# Cortex-M35P register map
Vendor: ARM Ltd.
CPU: Cortex-M35P r0p0, little endian, MPU, FPU, double-precision FPU, VTOR, vendor SysTick, 8 interrupt priority bits
Registers are 32-bit, read-write, no defined reset value unless marked. A register's access mark holds for its fields unless they carry their own. Offsets are from the block's base; [hi:lo] are bit positions; {n}, {i} and the like mark numbered series; 'fields as' and 'values as' point back to an identical list.

## NVIC — Nested Vectored Interrupt Controller
Base ?
0x00 NVIC_ISER{i} (i=0..15)
  [30:0] SETENA — Set enable
0x00 NVIC_ISPR{i} (i=0..15)
  [30:0] SETPEND — Set pending
0x80 NVIC_ICER{i} (i=0..15)
  [30:0] CLRENA — Clear enable
0x180 NVIC_ICPR{i} (i=0..15)
  [30:0] CLRPEND — Clear pending
0x200 NVIC_IABR{i} ro (i=0..15)
  [30:0] ACTIVE — Active state
0x280 NVIC_ITNS{i} (i=0..15)
  [30:0] ITNS — Interrupt Targets Non-secure
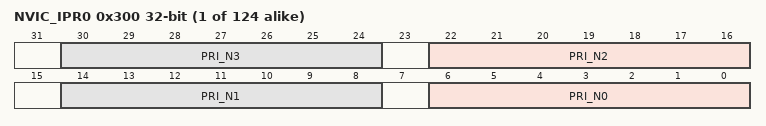
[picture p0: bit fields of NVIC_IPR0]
0x300 NVIC_IPR{i} (i=0..123)
  [8n+6:8n] PRI_N{n} (n=0..3) — Priority '{4i}'+{n}

## MPU — Memory protection Unit Control Registers
Base ?
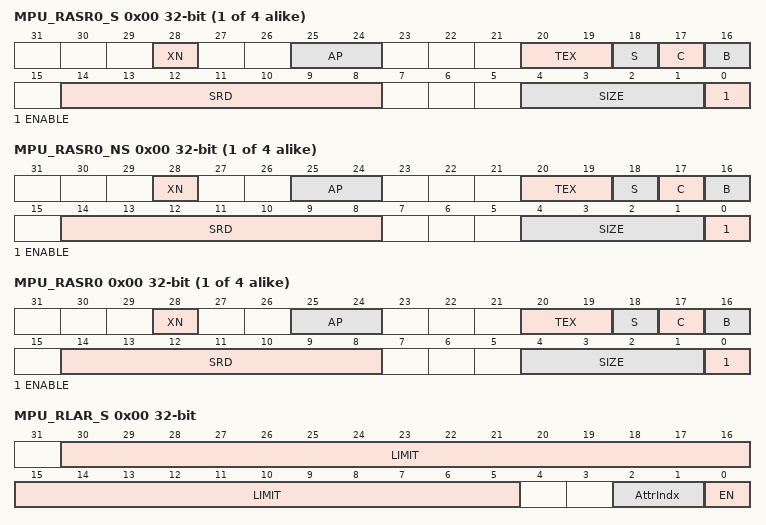
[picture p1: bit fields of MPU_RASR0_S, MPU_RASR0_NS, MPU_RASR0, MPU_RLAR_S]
0x00 MPU_RASR{i}_S (i=0..3)
  [28] XN, [25:24] AP, [20:19] TEX, [18] S, [17] C, [16] B, [14:8] SRD, [4:1] SIZE, [0] ENABLE
0x00 MPU_RASR{i}_NS (i=0..3)
  fields as MPU_RASR0_S
0x00 MPU_RASR{i} (i=0..3)
  fields as MPU_RASR0_S
0x00 MPU_RLAR_S
  [30:5] LIMIT — Limit address
  [2:1] AttrIndx — Attribute index
  [0] EN — Enable
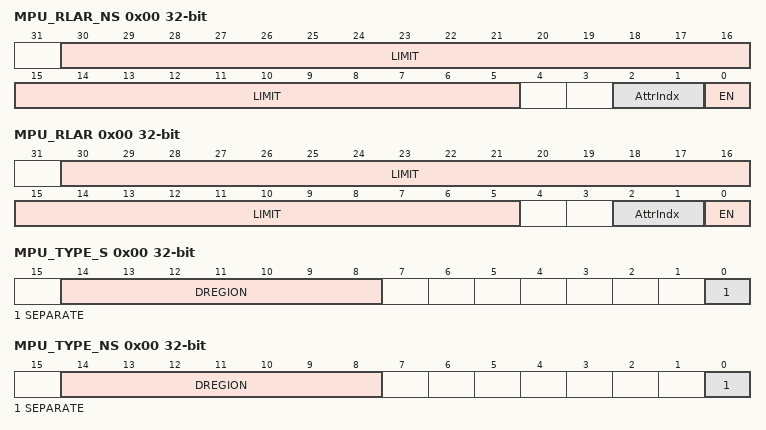
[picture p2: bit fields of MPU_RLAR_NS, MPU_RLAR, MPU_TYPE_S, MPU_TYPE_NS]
0x00 MPU_RLAR_NS
  fields as MPU_RLAR_S
0x00 MPU_RLAR
  fields as MPU_RLAR_S
0x00 MPU_TYPE_S ro
  [14:8] DREGION — Data regions
  [0] SEPARATE
0x00 MPU_TYPE_NS ro
  [14:8] DREGION — Data regions
  [0] SEPARATE
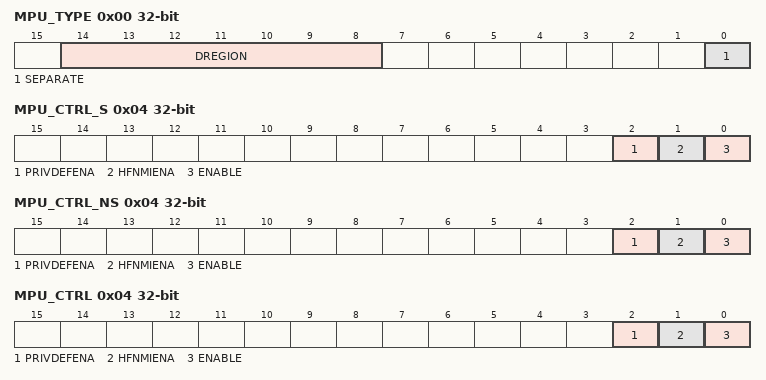
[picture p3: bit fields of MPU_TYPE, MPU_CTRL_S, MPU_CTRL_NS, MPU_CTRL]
0x00 MPU_TYPE ro
  [14:8] DREGION — Data regions
  [0] SEPARATE
0x04 MPU_CTRL_S
  [2] PRIVDEFENA — Privileged default enable
  [1] HFNMIENA — HardFault, NMI enable
  [0] ENABLE
0x04 MPU_CTRL_NS
  fields as MPU_CTRL_S
0x04 MPU_CTRL
  fields as MPU_CTRL_S
0x08 MPU_RNR_S
  [6:0] REGION — Region number
0x08 MPU_RNR_NS
  [6:0] REGION — Region number
0x08 MPU_RNR
  [6:0] REGION — Region number
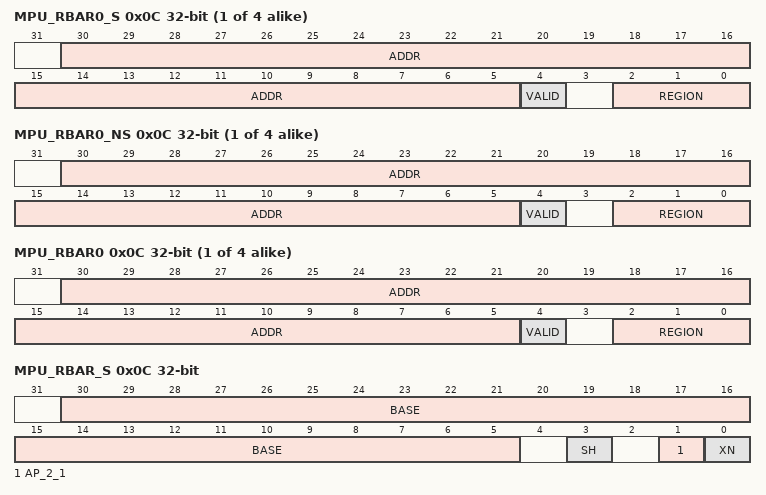
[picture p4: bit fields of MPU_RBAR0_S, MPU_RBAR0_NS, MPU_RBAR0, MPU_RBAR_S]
0x0C MPU_RBAR{i}_S (i=0..3)
  [30:5] ADDR, [4] VALID, [2:0] REGION
0x0C MPU_RBAR{i}_NS (i=0..3)
  [30:5] ADDR, [4] VALID, [2:0] REGION
0x0C MPU_RBAR{i} (i=0..3)
  [30:5] ADDR, [4] VALID, [2:0] REGION
0x0C MPU_RBAR_S
  [30:5] BASE — Base address
  [3] SH — Shareability
  [1] AP_2_1 — Access permissions
  [0] XN — Execute Never
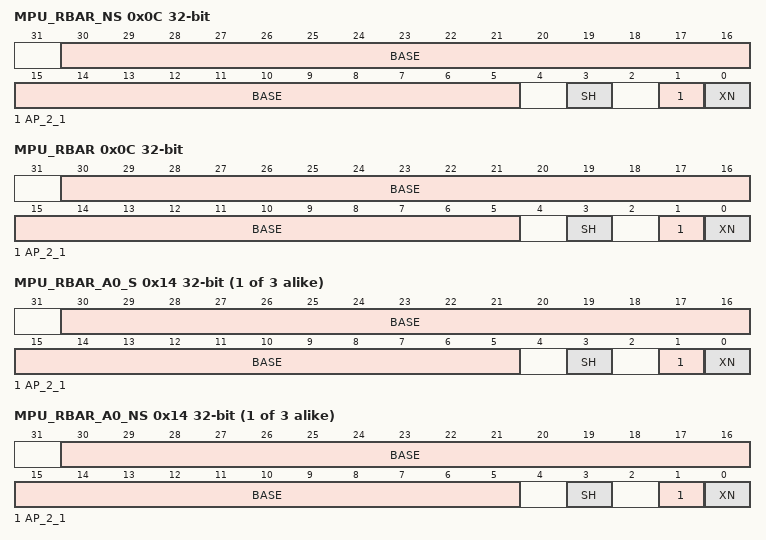
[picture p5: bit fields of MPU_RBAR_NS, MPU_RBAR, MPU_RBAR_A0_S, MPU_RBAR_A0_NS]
0x0C MPU_RBAR_NS
  fields as MPU_RBAR_S
0x0C MPU_RBAR
  fields as MPU_RBAR_S
0x14 MPU_RBAR_A{i}_S (i=0..2)
  fields as MPU_RBAR_S
0x14 MPU_RBAR_A{i}_NS (i=0..2)
  fields as MPU_RBAR_S
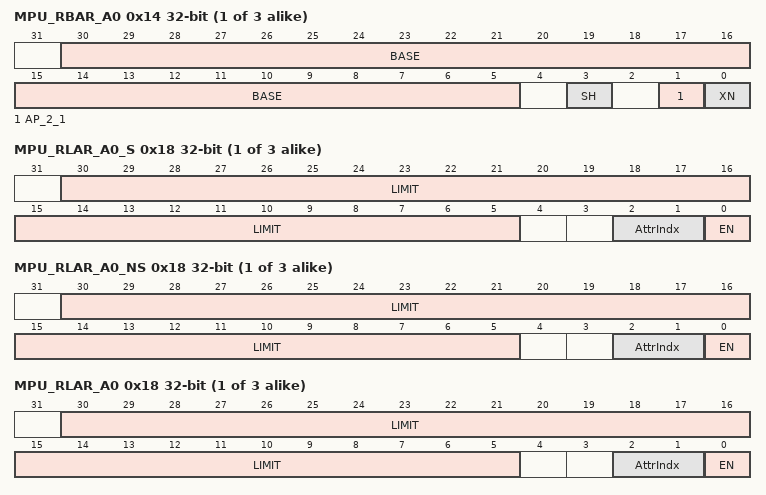
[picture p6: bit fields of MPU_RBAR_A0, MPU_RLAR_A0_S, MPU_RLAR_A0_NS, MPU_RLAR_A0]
0x14 MPU_RBAR_A{i} (i=0..2)
  fields as MPU_RBAR_S
0x18 MPU_RLAR_A{i}_S (i=0..2)
  fields as MPU_RLAR_S
0x18 MPU_RLAR_A{i}_NS (i=0..2)
  fields as MPU_RLAR_S
0x18 MPU_RLAR_A{i} (i=0..2)
  fields as MPU_RLAR_S
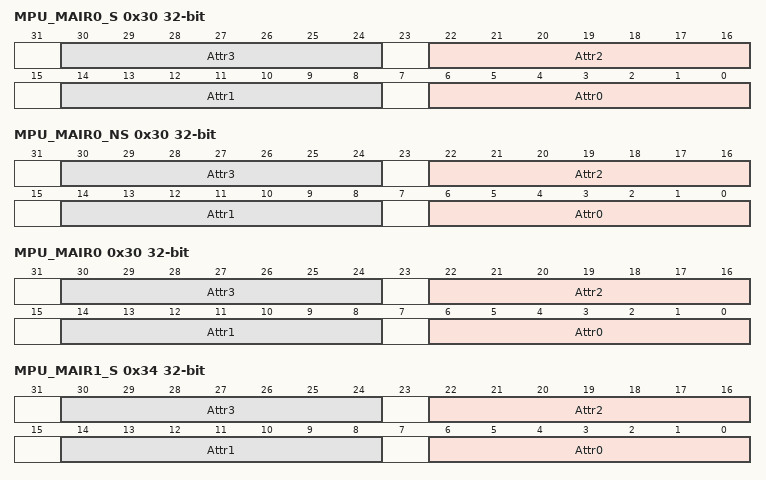
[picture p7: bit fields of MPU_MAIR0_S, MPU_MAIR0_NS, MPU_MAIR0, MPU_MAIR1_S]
0x30 MPU_MAIR0_S
  [8n+6:8n] Attr{n} (n=0..3) — Attribute {n}
0x30 MPU_MAIR0_NS
  [8n+6:8n] Attr{n} (n=0..3) — Attribute {n}
0x30 MPU_MAIR0
  [8n+6:8n] Attr{n} (n=0..3) — Attribute {n}
0x34 MPU_MAIR1_S
  [8n+6:8n] Attr{n} (n=0..3) — Attribute {n}
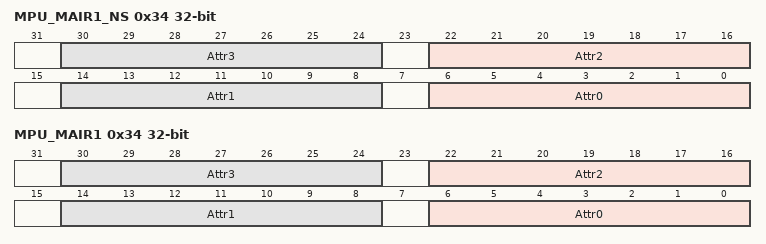
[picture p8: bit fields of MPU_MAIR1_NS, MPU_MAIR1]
0x34 MPU_MAIR1_NS
  [8n+6:8n] Attr{n} (n=0..3) — Attribute {n}
0x34 MPU_MAIR1
  [8n+6:8n] Attr{n} (n=0..3) — Attribute {n}

## SIG — Software Interrupt Control
Base ?
0x00 STIR wo
  [7:0] INTID — Interrupt ID

## SYST — SysTick Control Registers
Base ?
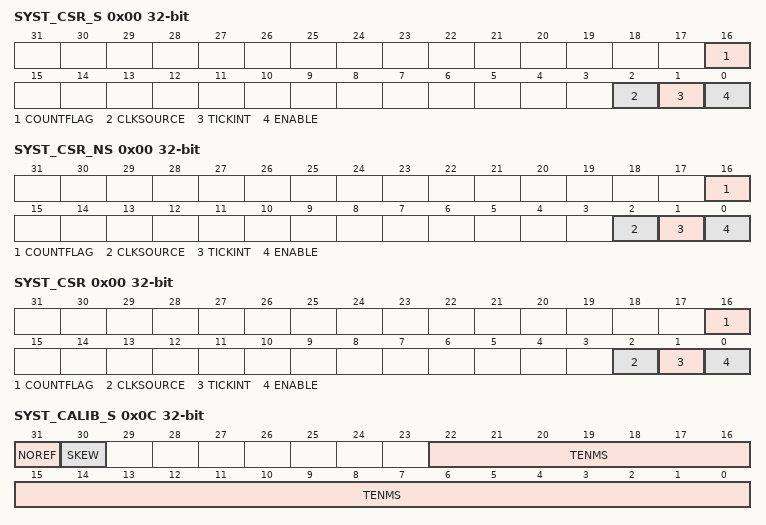
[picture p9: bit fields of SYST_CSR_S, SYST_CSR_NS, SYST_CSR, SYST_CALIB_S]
0x00 SYST_CSR_S
  [16] COUNTFLAG
  [2] CLKSOURCE — Clock source
  [1] TICKINT — Tick interrupt
  [0] ENABLE — SysTick enable
0x00 SYST_CSR_NS
  fields as SYST_CSR_S
0x00 SYST_CSR
  fields as SYST_CSR_S
0x04 SYST_RVR_S
  [22:0] RELOAD — Counter reload value
0x04 SYST_RVR_NS
  [22:0] RELOAD — Counter reload value
0x04 SYST_RVR
  [22:0] RELOAD — Counter reload value
0x08 SYST_CVR_S
  [22:0] CURRENT — Current counter value
0x08 SYST_CVR_NS
  [22:0] CURRENT — Current counter value
0x08 SYST_CVR
  [22:0] CURRENT — Current counter value
0x0C SYST_CALIB_S ro
  [31] NOREF — No reference
  [30] SKEW
  [22:0] TENMS — Ten milliseconds
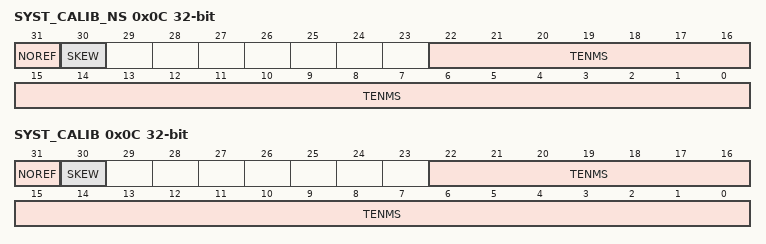
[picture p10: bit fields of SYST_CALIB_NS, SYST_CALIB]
0x0C SYST_CALIB_NS ro
  fields as SYST_CALIB_S
0x0C SYST_CALIB ro
  fields as SYST_CALIB_S

## SAU — Security Attribute Unit
Base ?
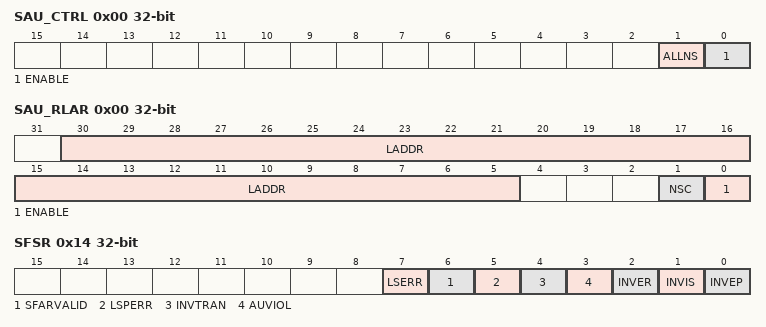
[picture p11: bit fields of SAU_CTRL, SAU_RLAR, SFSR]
0x00 SAU_CTRL
  [1] ALLNS — All Non-secure
  [0] ENABLE
0x00 SAU_RLAR
  [30:5] LADDR — Limit address
  [1] NSC — Non-secure callable
  [0] ENABLE
0x04 SAU_TYPE ro
  [6:0] SREGION — SAU regions
0x08 SAU_RNR
  [6:0] REGION — Region number
0x0C SAU_RBAR
  [30:5] BADDR — Base address
0x14 SFSR
  [7] LSERR — Lazy state error flag
  [6] SFARVALID — Secure fault address valid
  [5] LSPERR — Lazy state preservation error flag
  [4] INVTRAN — Invalid transition flag
  [3] AUVIOL — Attribution unit violation flag
  [2] INVER — Invalid exception return flag
  [1] INVIS — Invalid integrity signature flag
  [0] INVEP — Invalid entry point
0x18 SFAR
  [30:0] ADDRESS
